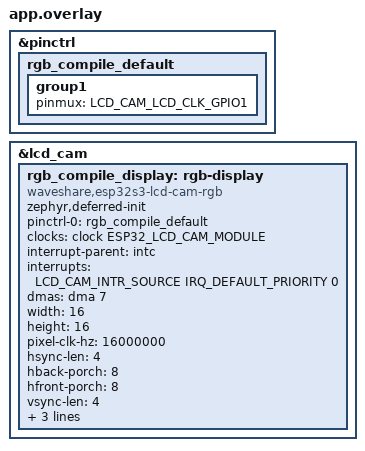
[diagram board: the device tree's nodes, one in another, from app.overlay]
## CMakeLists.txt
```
# SPDX-License-Identifier: Apache-2.0

cmake_minimum_required(VERSION 3.20)

get_filename_component(rgb_lcd_module_root "${CMAKE_CURRENT_SOURCE_DIR}/../.." ABSOLUTE)
list(APPEND ZEPHYR_EXTRA_MODULES "${rgb_lcd_module_root}")
list(REMOVE_DUPLICATES ZEPHYR_EXTRA_MODULES)

find_package(Zephyr REQUIRED HINTS $ENV{ZEPHYR_BASE})
project(rgb_lcd_module_build_check LANGUAGES C)
target_sources(app PRIVATE src/main.c)
```

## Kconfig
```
# SPDX-License-Identifier: Apache-2.0

mainmenu "RGB LCD module build check"

source "Kconfig.zephyr"
```

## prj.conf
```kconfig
CONFIG_DISPLAY=y
CONFIG_DISPLAY_WAVESHARE_ESP32S3_RGB=y
CONFIG_PINCTRL=y
CONFIG_LOG=y
CONFIG_HEAP_MEM_POOL_SIZE=16384
```

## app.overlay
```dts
/* Compile/link fixture only, not a panel wiring configuration. */
#include <zephyr/dt-bindings/pinctrl/esp32s3-pinctrl.h>

&pinctrl {
	rgb_compile_default: rgb_compile_default {
		group1 {
			pinmux = <LCD_CAM_LCD_CLK_GPIO1>;
		};
	};
};

&lcd_cam {
	rgb_compile_display: rgb-display {
		compatible = "waveshare,esp32s3-lcd-cam-rgb";
		status = "okay";
		zephyr,deferred-init;
		pinctrl-0 = <&rgb_compile_default>;
		pinctrl-names = "default";
		clocks = <&clock ESP32_LCD_CAM_MODULE>;
		interrupt-parent = <&intc>;
		interrupts = <LCD_CAM_INTR_SOURCE IRQ_DEFAULT_PRIORITY 0>;
		dmas = <&dma 7>;
		dma-names = "tx";
		width = <16>;
		height = <16>;
		pixel-clk-hz = <16000000>;
		hsync-len = <4>;
		hback-porch = <8>;
		hfront-porch = <8>;
		vsync-len = <4>;
		vback-porch = <8>;
		vfront-porch = <8>;
		data-width = <16>;
	};
};
```

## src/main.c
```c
#include <zephyr/device.h>
#include <zephyr/devicetree.h>
#include <zephyr/kernel.h>
#include <zephyr/sys/printk.h>

BUILD_ASSERT(IS_ENABLED(CONFIG_DISPLAY_WAVESHARE_ESP32S3_RGB),
	     "The build check must compile the RGB display driver");
BUILD_ASSERT(DT_HAS_COMPAT_STATUS_OKAY(waveshare_esp32s3_lcd_cam_rgb),
	     "The build check requires an enabled RGB display node");

int main(void)
{
	const struct device *display = DEVICE_DT_GET(DT_NODELABEL(rgb_compile_display));

	if (device_is_ready(display)) {
		printk("ERROR: the compile-only display was initialized unexpectedly.\n");
		return 1;
	}

	printk("RGB LCD module compile/link check; display initialization is deferred.\n");
	return 0;
}
```
